# STM32MP157 register map
File version: 1.6
CPU: CM4 r0p1, little endian, no MPU, FPU, 4 interrupt priority bits
Registers are 32-bit, read-write, reset 0x0 unless marked. A register's access mark holds for its fields unless they carry their own. Offsets are from the block's base; [hi:lo] are bit positions; 'fields as' and 'values as' point back to an identical list.

## ETH_DMA
Base 0x5800B000
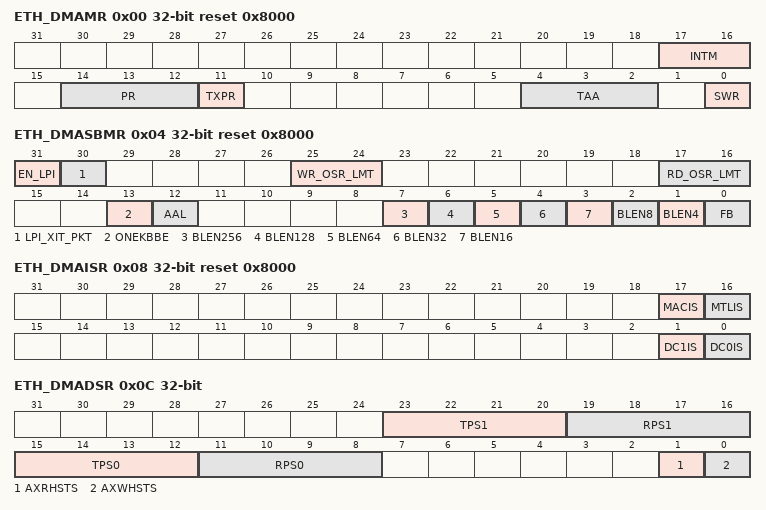
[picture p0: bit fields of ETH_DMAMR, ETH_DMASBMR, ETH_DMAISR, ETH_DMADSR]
0x00 ETH_DMAMR reset 0x8000 — DMA mode register
  [17:16] INTM — Interrupt Mode
  [14:12] PR — Priority ratio
  [11] TXPR — Transmit priority
  [4:2] TAA
  [0] SWR — Software Reset
0x04 ETH_DMASBMR reset 0x8000 — System bus mode register
  [31] EN_LPI
  [30] LPI_XIT_PKT
  [25:24] WR_OSR_LMT
  [17:16] RD_OSR_LMT
  [13] ONEKBBE
  [12] AAL — Address-Aligned Beats
  [7] BLEN256
  [6] BLEN128
  [5] BLEN64
  [4] BLEN32
  [3] BLEN16
  [2] BLEN8
  [1] BLEN4
  [0] FB — Fixed Burst Length
0x08 ETH_DMAISR ro reset 0x8000 — Interrupt status register
  [17] MACIS — MAC Interrupt Status
  [16] MTLIS — MTL Interrupt Status
  [1] DC1IS
  [0] DC0IS — DMA Channel Interrupt Status
0x0C ETH_DMADSR ro — Debug status register
  [23:20] TPS1
  [19:16] RPS1
  [15:12] TPS0
  [11:8] RPS0
  [1] AXRHSTS
  [0] AXWHSTS — AHB Master Write Channel
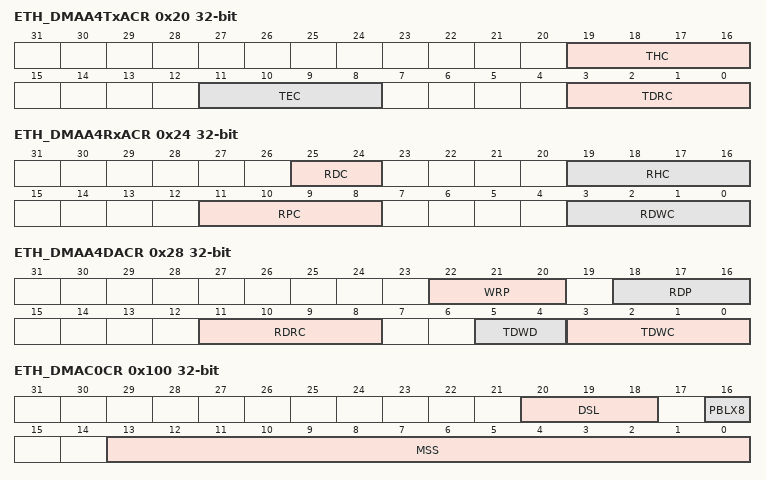
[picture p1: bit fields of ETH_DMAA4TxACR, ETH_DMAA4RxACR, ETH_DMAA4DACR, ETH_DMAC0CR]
0x20 ETH_DMAA4TxACR — AXI4 transmit channel ACE control register
  [19:16] THC, [11:8] TEC, [3:0] TDRC
0x24 ETH_DMAA4RxACR — AXI4 receive channel ACE control register
  [25:24] RDC, [19:16] RHC, [11:8] RPC, [3:0] RDWC
0x28 ETH_DMAA4DACR — AXI4 descriptor ACE control register
  [22:20] WRP, [18:16] RDP, [11:8] RDRC, [5:4] TDWD, [3:0] TDWC
0x100 ETH_DMAC0CR — Channel 0 control register
  [20:18] DSL, [16] PBLX8, [13:0] MSS
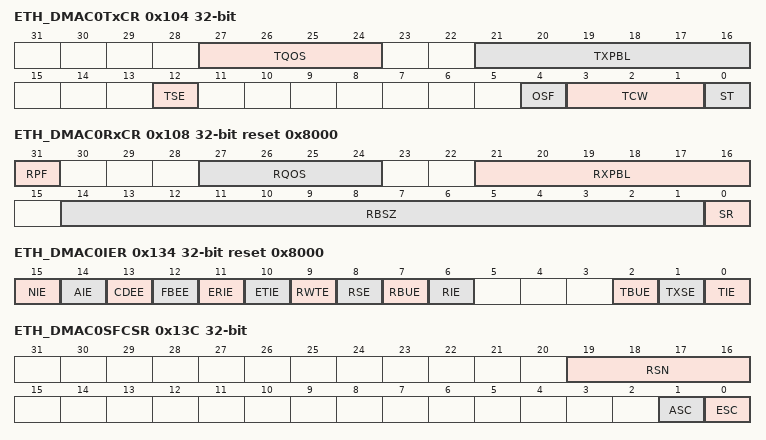
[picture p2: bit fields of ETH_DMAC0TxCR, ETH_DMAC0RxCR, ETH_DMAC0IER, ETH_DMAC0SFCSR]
0x104 ETH_DMAC0TxCR — Channel 0 transmit control register
  [27:24] TQOS, [21:16] TXPBL, [12] TSE, [4] OSF, [3:1] TCW, [0] ST
0x108 ETH_DMAC0RxCR reset 0x8000 — Channel receive control register
  [31] RPF — DMA Rx Channel Packet Flush
  [27:24] RQOS
  [21:16] RXPBL
  [14:1] RBSZ — Receive Buffer size
  [0] SR — Start or Stop Receive Command
0x114 ETH_DMAC0TxDLAR — Channel i Tx descriptor list address register
  [31:3] TDESLA — Start of Transmit List
0x11C ETH_DMAC0RxDLAR reset 0x8000 — Channel Rx descriptor list address register
  [31:3] RDESLA — Start of Receive List
0x120 ETH_DMAC0TxDTPR — Channel Tx descriptor tail pointer register
  [31:3] TDT — Transmit Descriptor Tail Pointer
0x128 ETH_DMAC0RxDTPR — Channel Rx descriptor tail pointer register
  [31:3] RDT — Receive Descriptor Tail Pointer
0x12C ETH_DMAC0TxRLR — Channel Tx descriptor ring length register
  [9:0] TDRL — Transmit Descriptor Ring Length
0x130 ETH_DMAC0RxRLR reset 0x8000 — Channel Rx descriptor ring length register
  [9:0] RDRL — Receive Descriptor Ring Length
0x134 ETH_DMAC0IER reset 0x8000 — Channel interrupt enable register
  [15] NIE — Normal Interrupt Summary Enable
  [14] AIE — Abnormal Interrupt Summary Enable
  [13] CDEE — Context Descriptor Error Enable
  [12] FBEE — Fatal Bus Error Enable
  [11] ERIE — Early Receive Interrupt Enable
  [10] ETIE — Early Transmit Interrupt Enable
  [9] RWTE — Receive Watchdog Timeout Enable
  [8] RSE — Receive Stopped Enable
  [7] RBUE — Receive Buffer Unavailable Enable
  [6] RIE — Receive Interrupt Enable
  [2] TBUE — Transmit Buffer Unavailable Enable
  [1] TXSE — Transmit Stopped Enable
  [0] TIE — Transmit Interrupt Enable
0x138 ETH_DMAC0RxIWTR — Channel Rx interrupt watchdog timer register
  [7:0] RWT — Receive Interrupt Watchdog Timer Count
0x13C ETH_DMAC0SFCSR — Channel i slot function control status register
  [19:16] RSN, [1] ASC, [0] ESC
0x144 ETH_DMAC0CATxDR ro — Channel current application transmit descriptor register
  [31:0] CURTDESAPTR — Application Transmit Descriptor Address Pointer
0x14C ETH_DMAC0CARxDR ro (alternate view of DMAC1CATxDR) — Channel 0 current application receive descriptor register
  [31:0] CURRDESAPTR — Application Transmit Descriptor Address Pointer
0x154 ETH_DMAC0CATxBR ro — Channel 0 current application transmit buffer register
  [31:0] CURTBUFAPTR — Application Transmit Buffer Address Pointer
0x15C ETH_DMAC0CARxBR ro — Channel current application receive buffer register
  [31:0] CURRBUFAPTR — Application Receive Buffer Address Pointer
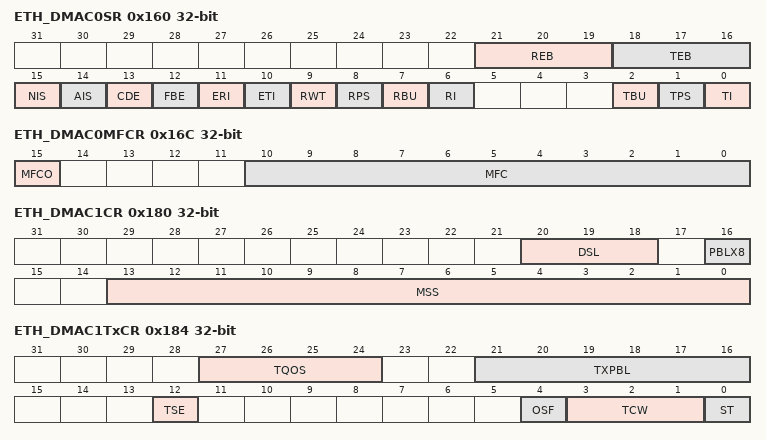
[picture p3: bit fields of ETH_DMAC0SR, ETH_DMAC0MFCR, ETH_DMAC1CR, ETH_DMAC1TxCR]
0x160 ETH_DMAC0SR — Channel status register
  [21:19] REB — Rx DMA Error Bits
  [18:16] TEB — Tx DMA Error Bits
  [15] NIS — Normal Interrupt Summary
  [14] AIS — Abnormal Interrupt Summary
  [13] CDE — Context Descriptor Error
  [12] FBE — Fatal Bus Error
  [11] ERI — Early Receive Interrupt
  [10] ETI — Early Transmit Interrupt
  [9] RWT — Receive Watchdog Timeout
  [8] RPS — Receive Process Stopped
  [7] RBU — Receive Buffer Unavailable
  [6] RI — Receive Interrupt
  [2] TBU — Transmit Buffer Unavailable
  [1] TPS — Transmit Process Stopped
  [0] TI — Transmit Interrupt
0x16C ETH_DMAC0MFCR ro — Channel missed frame count register
  [15] MFCO — Overflow status of the MFC Counter
  [10:0] MFC — Dropped Packet Counters
0x180 ETH_DMAC1CR — Channel 1 control register
  [20:18] DSL, [16] PBLX8, [13:0] MSS
0x184 ETH_DMAC1TxCR — Channel 1 transmit control register
  [27:24] TQOS, [21:16] TXPBL, [12] TSE, [4] OSF, [3:1] TCW, [0] ST
0x194 ETH_DMAC1TxDLAR — Channel i Tx descriptor list address register
  [31:3] TDESLA — Start of Transmit List
0x1A0 ETH_DMAC1TxDTPR — Channel Tx descriptor tail pointer register
  [31:3] TDT — Transmit Descriptor Tail Pointer
0x1AC ETH_DMAC1TxRLR — Channel Tx descriptor ring length register
  [9:0] TDRL — Transmit Descriptor Ring Length
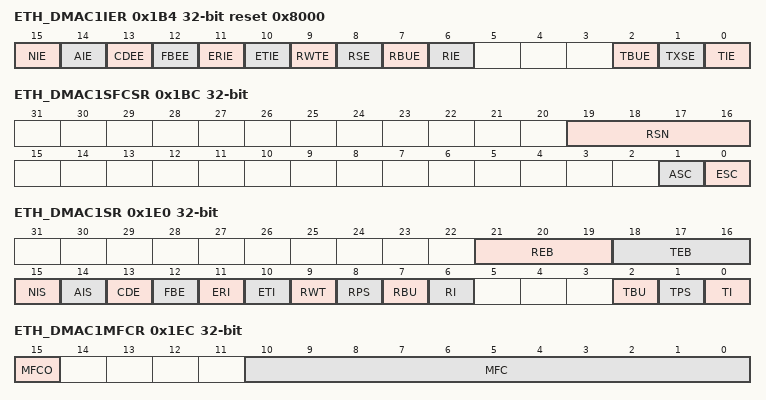
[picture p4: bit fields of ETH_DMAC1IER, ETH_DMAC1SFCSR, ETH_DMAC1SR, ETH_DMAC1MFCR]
0x1B4 ETH_DMAC1IER reset 0x8000 — Channel interrupt enable register
  fields as ETH_DMAC0IER
0x1BC ETH_DMAC1SFCSR — Channel i slot function control status register
  [19:16] RSN, [1] ASC, [0] ESC
0x1C4 ETH_DMAC1CATxDR ro — Channel current application transmit descriptor register
  [31:0] CURTDESAPTR — Application Transmit Descriptor Address Pointer
0x1D4 ETH_DMAC1CATxBR ro — Channel 0 current application transmit buffer register
  [31:0] CURTBUFAPTR — Application Transmit Buffer Address Pointer
0x1E0 ETH_DMAC1SR — Channel status register
  fields as ETH_DMAC0SR
0x1EC ETH_DMAC1MFCR ro — Channel missed frame count register
  fields as ETH_DMAC0MFCR
